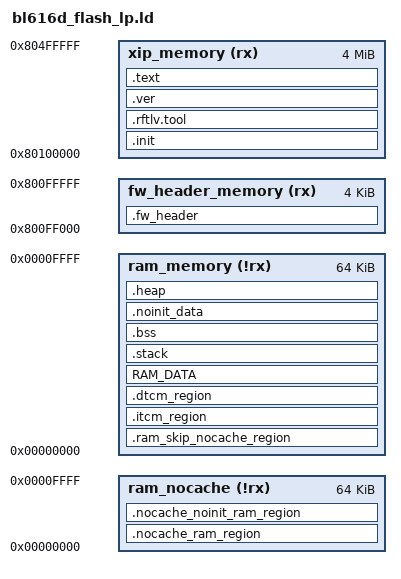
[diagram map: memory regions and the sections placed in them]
/****************************************************************************************
* @file flash.ld
*
* @brief This file is the link script file (gnuarm or armgcc).
*
* Copyright (C) BouffaloLab 2021
*
****************************************************************************************
*/

/* configure the CPU type */
OUTPUT_ARCH( "riscv" )

/* configure the entry point */
ENTRY(__start)

StackSize    = 0x0400; /*  1KB */
HeapMinSize  = 0x1000; /*  4KB */

__RFTLV_SIZE_OFFSET = 1K;
__RFTLV_SIZE_HOLE = 2K;
__RFTLV_HEAD1_H = (0x46524C42); /* BLRF */
__RFTLV_HEAD1_L = (0x41524150); /* PAPA */

/* Link stage feature control */
PROVIDE( __macsw_conf_bl_wifi_ps_enable = 0 );
PROVIDE( __macsw_conf_plat_dma_enable = 1 );

VerOffset = 0xc00;

MEMORY
{
    fw_header_memory  (rx)  : ORIGIN = 0x80100000 - 0x1000, LENGTH = 4K
    xip_memory  (rx)  : ORIGIN = 0x80100000, LENGTH = 4M
    ram_nocache (!rx) : ORIGIN = 0x00000000, LENGTH = 64K
    ram_memory (!rx) : ORIGIN = 0x00000000, LENGTH = 64K
}

SECTIONS
{
    .fw_header :
    {
        KEEP(*(.fw_header))
    } > fw_header_memory

    .init :
    {
        KEEP (*(SORT_NONE(.init)))
        KEEP (*(SORT_NONE(.vector)))

    } > xip_memory

    .rftlv.tool :
    {
        . = ORIGIN(xip_memory) + __RFTLV_SIZE_OFFSET;
        PROVIDE( _ld_symbol_rftlv_address = . );
        LONG(__RFTLV_HEAD1_H);
        LONG(__RFTLV_HEAD1_L);
        . = ORIGIN(xip_memory) + __RFTLV_SIZE_OFFSET + __RFTLV_SIZE_HOLE;
    } > xip_memory

    .ver : AT(ORIGIN(xip_memory) + VerOffset)
    {
		LONG(0x42464c42); /* BLFB */
		LONG(0x46524556); /* VERF */
		KEEP (*(.bflb_verinf))
		LONG(0x42464c42); /* BLFB */
		LONG(0x46524556); /* VERF */
		KEEP (*(.verinfo))
    } > xip_memory

    .text :
    {
        . = ALIGN(4);
        __text_code_start__ = .;

        *(EXCLUDE_FILE(*_udivdi3*.o*) .text*)

        /* section information for shell */
        . = ALIGN(4);
        __fsymtab_start = .;
        KEEP(*(FSymTab))
        __fsymtab_end = .;

        . = ALIGN(4);
        __vsymtab_start = .;
        KEEP(*(VSymTab))
        __vsymtab_end = .;

        /* section information for usb usbh_class_info */
        . = ALIGN(4);
        __usbh_class_info_start__ = .;
        KEEP(*(.usbh_class_info))
        . = ALIGN(4);
        __usbh_class_info_end__ = .;

        /* section information for components's version */
        . = ALIGN(4);
        _version_info_section_start = .;
        KEEP(*(.version.*))
        _version_info_section_end = .;

        /*put .rodata**/
        *(EXCLUDE_FILE( *bl616d_glb*.o* \
                        *bl616d_pds*.o* \
                        *bl616d_common*.o* \
                        *bl616d_sf_cfg*.o* \
                        *bl616d_sf_ctrl*.o* \
                        *bl616d_sflash*.o* \
                        *bl616d_xip_sflash*.o* \
                        *bl616d_ef_ctrl*.o* \
                        *bl616d_ef_cfg*.o* \
                        *bl616d_clock*.o* \
                        *_clz*.o* \
                        *bl616d_romapi_patch*.o* ).rodata*)

        *(.srodata)
        *(.srodata.*)

        /* _dump_sections for bflb_coredump.c*/
        . = ALIGN(4);
        PROVIDE( _dump_sections = ABSOLUTE(.));
        LONG(ORIGIN(ram_memory));
        LONG(LENGTH(ram_memory));
        LONG(0x28010000); /* bt memory */
        LONG(0xffffffff);
        LONG(0xffffffff);
        /* _dump_sections for bl_coredump.c*/

        . = ALIGN(4);
        __text_code_end__ = .;
    } > xip_memory

    . = ALIGN(4);
    __nocache_ram_load_addr = .;

    .nocache_ram_region  : AT (__nocache_ram_load_addr)
    {
        . = ALIGN(4);
        __nocache_ram_data_start__ = .;

        *(.nocache_ram)

        . = ALIGN(4);
        __nocache_ram_data_end__ = .;
    } > ram_nocache

    .nocache_noinit_ram_region (NOLOAD) :
    {
        . = ALIGN(4);
        __nocache_noinit_ram_data_start__ = .;

        *(.nocache_noinit_ram)
        *(.noncacheable)

        . = ALIGN(4);
        __nocache_noinit_ram_data_end__ = .;
    } > ram_nocache

    /* Skip the nocache region */
    .ram_skip_nocache_region (NOLOAD) :
    {
        . += (__nocache_noinit_ram_data_end__ - ORIGIN(ram_nocache));
    } > ram_memory

    __itcm_load_addr = __nocache_ram_load_addr + SIZEOF(.nocache_ram_region);

    .itcm_region : AT (__itcm_load_addr)
    {
        . = ALIGN(4);
        __tcm_code_start__ = .;

        *(.tcm_code.*)
        *(.tcm_const.*)
        *(.sclock_rlt_code.*)
        *(.sclock_rlt_const.*)

        *bl616d_glb*.o*(.rodata*)
        *bl616d_pds*.o*(.rodata*)
        *bl616d_common*.o*(.rodata*)
        *bl616d_sf_cfg*.o*(.rodata*)
        *bl616d_sf_ctrl*.o*(.rodata*)
        *bl616d_sflash*.o*(.rodata*)
        *bl616d_xip_sflash*.o*(.rodata*)
        *bl616d_ef_ctrl*.o*(.rodata*)
        *bl616d_ef_cfg*.o*(.rodata*)
        *bl616d_clock*.o*(.rodata*)
        *_clz*.o*(.rodata*)
        *bl616d_romapi_patch*.o*(.rodata*)

        *_udivdi3*.o*(.text*)

        . = ALIGN(4);
        __tcm_code_end__ = .;
    } > ram_memory

    __dtcm_load_addr = __itcm_load_addr + SIZEOF(.itcm_region);

    .dtcm_region : AT (__dtcm_load_addr)
    {
        . = ALIGN(4);
        __tcm_data_start__ = .;

        *(.tcm_data)
        /* *finger_print.o(.data*) */

        . = ALIGN(4);
        __tcm_data_end__ = .;
    } > ram_memory

    __ram_load_addr = __dtcm_load_addr + SIZEOF(.dtcm_region);

    /* Data section */
    RAM_DATA : AT (__ram_load_addr)
    {
        . = ALIGN(4);
        __ram_data_start__ = .;

        PROVIDE( __global_pointer$ = . + 0x800 );

        *(.data)
        *(.data.*)
        *(.sdata)
        *(.sdata.*)
        *(.sdata2)
        *(.sdata2.*)

        . = ALIGN(8);
        *(._k_queue.static.*)
        *(._k_sem.static.*)
        *(._k_mutex.static.*)
        _bt_gatt_service_static_list_start = .;
        KEEP(*(SORT_BY_NAME("._bt_gatt_service_static.static.*")))
        _bt_gatt_service_static_list_end = .;
        _bt_l2cap_fixed_chan_list_start = .;
        KEEP(*(SORT_BY_NAME("._bt_l2cap_fixed_chan.static.*")))
        _bt_l2cap_fixed_chan_list_end = .;
        _bt_l2cap_br_fixed_chan_list_start = .;
        KEEP(*(SORT_BY_NAME("._bt_l2cap_br_fixed_chan.static.*")))
        _bt_l2cap_br_fixed_chan_list_end = .;

        . = ALIGN(4);
        __bflb_log_tags_start__ = .;
        *(.bflb_log_tags_array)
        . = ALIGN(4);
        __bflb_log_tags_end__ = .;
        __ram_data_end__ = .;
    } > ram_memory


    __etext_final = (__ram_load_addr + SIZEOF (RAM_DATA));
    ASSERT(__etext_final <= ORIGIN(xip_memory) + LENGTH(xip_memory), "code memory overflow")

    .stack (NOLOAD):
    {
        __StackLimit = .;
        . = ALIGN(16);
        . = . + StackSize;
        __StackTop = .;
        __freertos_irq_stack_top = .;

        /* for CPU_NP */
        . = . + StackSize;
        __StackTop_NP = .;
    } > ram_memory

    PROVIDE( __freertos_irq_stack_top = __StackTop);
    PROVIDE( _sp_main = __StackTop);
    PROVIDE( _sp_base = __StackLimit);

    .bss (NOLOAD) :
    {
        . = ALIGN(4);
        __bss_start__ = .;

        *(.bss*)
        *(.sbss*)
        *(COMMON)

        . = ALIGN(4);
        __bss_end__ = .;
    } > ram_memory

    .noinit_data (NOLOAD) :
    {
        . = ALIGN(4);
        __noinit_data_start__ = .;

        *(.noinit_data*)

        . = ALIGN(4);
        __noinit_data_end__ = .;
    } > ram_memory

    .heap (NOLOAD):
    {
        . = ALIGN(4);
        __HeapBase = .;

        KEEP(*(.heap*))

        . = ALIGN(4);
        __HeapLimit = .;
    } > ram_memory

    __HeapLimit = ORIGIN(ram_memory) + LENGTH(ram_memory);
    ASSERT(__HeapLimit - __HeapBase >= HeapMinSize, "heap region overflow")

}
